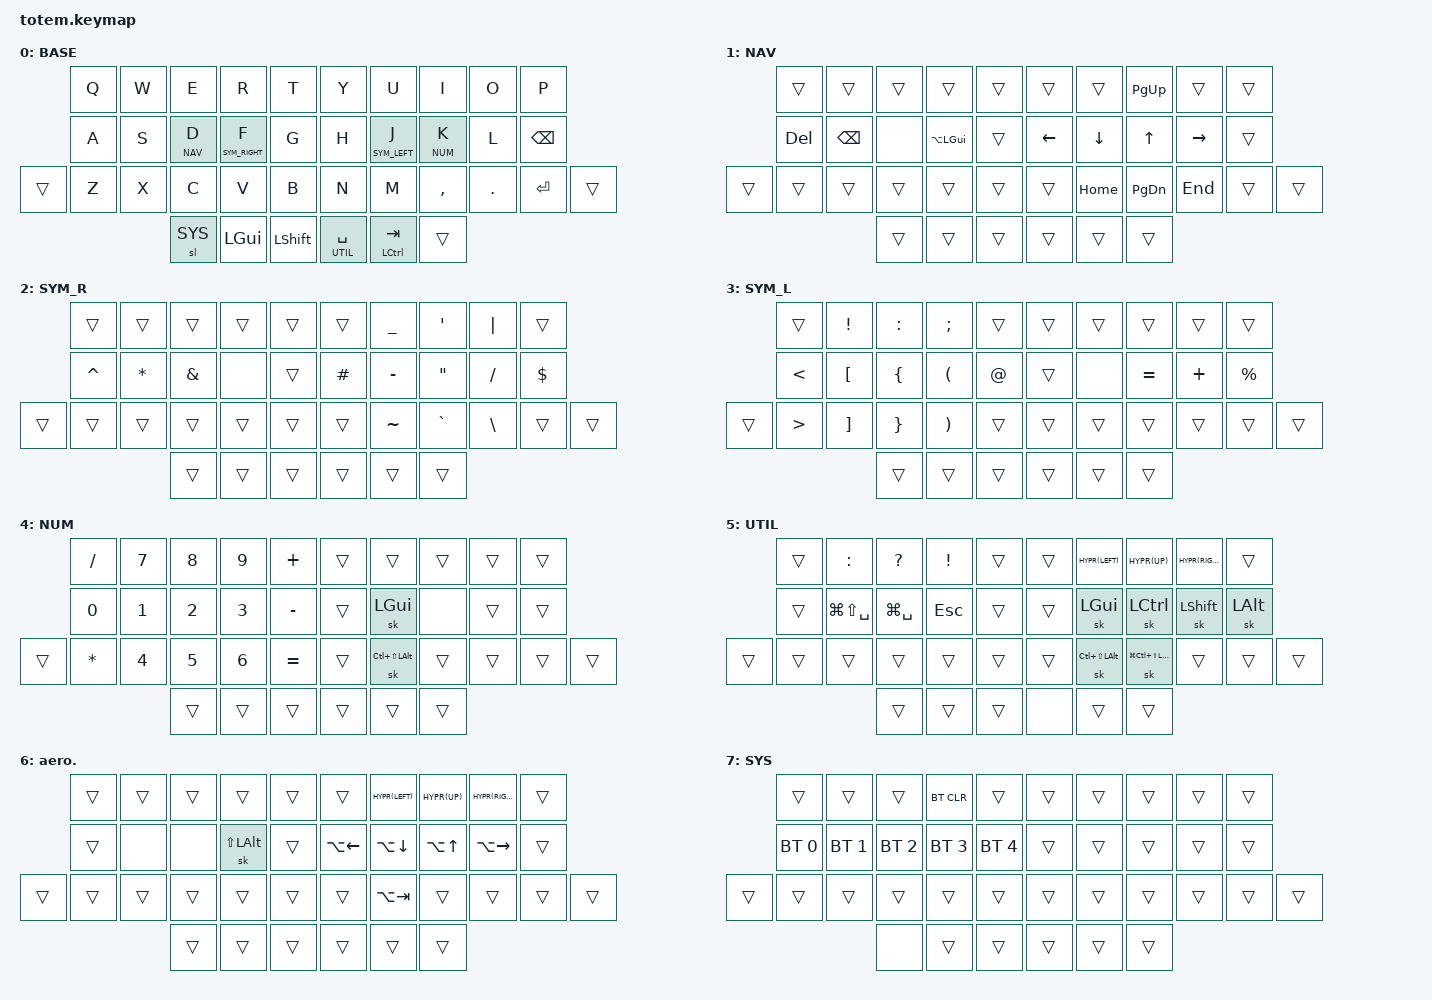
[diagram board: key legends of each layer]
#include <behaviors.dtsi>
#include <dt-bindings/zmk/keys.h>
#include <dt-bindings/zmk/bt.h>
#include <dt-bindings/zmk/outputs.h>

// Layer definitions
#define BASE 0
#define NAV 1
#define SYM_RIGHT 2
#define SYM_LEFT 3
#define NUM 4
#define UTIL 5
#define AERO 6
#define SYS 7

#define QUICK_TAP_MS 175

// QMK-like keycodes
#define _XXX &none
#define ____ &trans

#define _HYPR(kc) &kp LC(LS(LA(LG(kc))))
#define _MEH(kc) &kp LC(LS(LA(kc)))

#define _RAYCAST &kp LG(SPACE)
#define _1PASS &kp LG(LS(SPACE))

// Sticky mods - named explicitly here because I forget what they're are
#define _SK_AERO &sk LS(LALT)
#define _SK_MEH &sk LC(LS(LALT))
#define _SK_HYPR &sk LG(LC(LS(LALT)))

&mt {
  flavor = "balanced";
  tapping-term-ms = <280>;
  quick-tap-ms = <QUICK_TAP_MS>;
  global-quick-tap;
};

&sk {
  release-after-ms = <900>;
  quick-release;
};

&lt {
  flavor = "balanced";
  tapping-term-ms = <200>;
  quick-tap-ms = <QUICK_TAP_MS>;
};

/ {
	combos {
		compatible = "zmk,combos";

		// left ring and index finger
		combo_aero {
			timeout-ms = <200>;
			key-positions = <11 12>;
			bindings = <&mo AERO>;
		};
	};

  keymap {
    compatible = "zmk,keymap";

    base {
      label = "BASE";
      bindings = <
//           ┌───┬───┬──────────┬───────────────┬──────┐   ┌─────────────┬───────────────┬──────────┬───┬──────┐
//           │ Q │ W │    E     │       R       │  T   │   │      Y      │       U       │    I     │ O │  P   │
//           ├───┼───┼──────────┼───────────────┼──────┤   ├─────────────┼───────────────┼──────────┼───┼──────┤
//           │ A │ S │ lt NAV D │ lt SYM_rght F │  G   │   │      H      │ lt SYM_left J │ lt NUM K │ L │ bspc │
//    ┌──────┼───┼───┼──────────┼───────────────┼──────┤   ├─────────────┼───────────────┼──────────┼───┼──────┼──────┐
//    │ ____ │ Z │ X │    C     │       V       │  B   │   │      N      │       M       │    ,     │ . │ ent  │ ____ │
//    └──────┴───┴───┼──────────┼───────────────┼──────┤   ├─────────────┼───────────────┼──────────┼───┴──────┴──────┘
//                   │  sl SYS  │     lgui      │ lsft │   │ lt UTIL spc │ mt lctlTL tab │   ____   │
//                   └──────────┴───────────────┴──────┘   └─────────────┴───────────────┴──────────┘
         &kp Q   &kp W   &kp E       &kp R             &kp T            &kp Y            &kp U            &kp I       &kp O     &kp P
         &kp A   &kp S   &lt NAV D   &lt SYM_RIGHT F   &kp G            &kp H            &lt SYM_LEFT J   &lt NUM K   &kp L     &kp BSPC
  ____   &kp Z   &kp X   &kp C       &kp V             &kp B            &kp N            &kp M            &kp COMMA   &kp DOT   &kp ENTER   ____
                         &sl SYS     &kp LGUI          &kp LSHIFT       &lt UTIL SPACE   &mt LCTL TAB     ____
      >;
    };

    nav {
      label = "NAV";
      bindings = <
//           ┌──────┬──────┬──────┬────────────┬──────┐   ┌──────┬──────┬──────┬──────┬──────┐
//           │ ____ │ ____ │ ____ │    ____    │ ____ │   │ ____ │ ____ │ pgup │ ____ │ ____ │
//           ├──────┼──────┼──────┼────────────┼──────┤   ├──────┼──────┼──────┼──────┼──────┤
//           │ del  │ bspc │ _XXX │ lalt(lgui) │ ____ │   │ left │ down │  up  │ rght │ ____ │
//    ┌──────┼──────┼──────┼──────┼────────────┼──────┤   ├──────┼──────┼──────┼──────┼──────┼──────┐
//    │ ____ │ ____ │ ____ │ ____ │    ____    │ ____ │   │ ____ │ home │ pgdn │ end  │ ____ │ ____ │
//    └──────┴──────┴──────┼──────┼────────────┼──────┤   ├──────┼──────┼──────┼──────┴──────┴──────┘
//                         │ ____ │    ____    │ ____ │   │ ____ │ ____ │ ____ │
//                         └──────┴────────────┴──────┘   └──────┴──────┴──────┘
         ____      ____       ____   ____           ____       ____       ____       &kp PG_UP   ____        ____
         &kp DEL   &kp BSPC   _XXX   &kp LA(LGUI)   ____       &kp LEFT   &kp DOWN   &kp UP      &kp RIGHT   ____
  ____   ____      ____       ____   ____           ____       ____       &kp HOME   &kp PG_DN   &kp END     ____   ____
                              ____   ____           ____       ____       ____       ____
      >;
    };

    sym_right {
      label = "SYM_R";
      bindings = <
//           ┌──────┬──────┬──────┬──────┬──────┐   ┌──────┬──────┬──────┬───┬──────┐
//           │ ____ │ ____ │ ____ │ ____ │ ____ │   │ ____ │  _   │  '   │ | │ ____ │
//           ├──────┼──────┼──────┼──────┼──────┤   ├──────┼──────┼──────┼───┼──────┤
//           │  ^   │  *   │  &   │ _XXX │ ____ │   │  #   │  -   │  "   │ / │  $   │
//    ┌──────┼──────┼──────┼──────┼──────┼──────┤   ├──────┼──────┼──────┼───┼──────┼──────┐
//    │ ____ │ ____ │ ____ │ ____ │ ____ │ ____ │   │ ____ │  ~   │  `   │ \ │ ____ │ ____ │
//    └──────┴──────┴──────┼──────┼──────┼──────┤   ├──────┼──────┼──────┼───┴──────┴──────┘
//                         │ ____ │ ____ │ ____ │   │ ____ │ ____ │ ____ │
//                         └──────┴──────┴──────┘   └──────┴──────┴──────┘
         ____        ____       ____       ____   ____       ____       &kp UNDER   &kp SQT     &kp PIPE   ____
         &kp CARET   &kp STAR   &kp AMPS   _XXX   ____       &kp HASH   &kp MINUS   &kp DQT     &kp FSLH   &kp DOLLAR
  ____   ____        ____       ____       ____   ____       ____       &kp TILDE   &kp GRAVE   &kp BSLH   ____         ____
                                ____       ____   ____       ____       ____        ____
      >;
    };

    sym_left {
      label = "SYM_L";
      bindings = <
//           ┌──────┬───┬──────┬──────┬──────┐   ┌──────┬──────┬──────┬──────┬──────┐
//           │ ____ │ ! │  :   │  ;   │ ____ │   │ ____ │ ____ │ ____ │ ____ │ ____ │
//           ├──────┼───┼──────┼──────┼──────┤   ├──────┼──────┼──────┼──────┼──────┤
//           │  <   │ [ │  {   │  (   │  @   │   │ ____ │ _XXX │ EQL  │  +   │  %   │
//    ┌──────┼──────┼───┼──────┼──────┼──────┤   ├──────┼──────┼──────┼──────┼──────┼──────┐
//    │ ____ │  >   │ ] │  }   │  )   │ ____ │   │ ____ │ ____ │ ____ │ ____ │ ____ │ ____ │
//    └──────┴──────┴───┼──────┼──────┼──────┤   ├──────┼──────┼──────┼──────┴──────┴──────┘
//                      │ ____ │ ____ │ ____ │   │ ____ │ ____ │ ____ │
//                      └──────┴──────┴──────┘   └──────┴──────┴──────┘
         ____     &kp EXCL   &kp COLON   &kp SEMI   ____         ____   ____   ____      ____       ____
         &kp LT   &kp LBKT   &kp LBRC    &kp LPAR   &kp AT       ____   _XXX   &kp EQL   &kp PLUS   &kp PERCENT
  ____   &kp GT   &kp RBKT   &kp RBRC    &kp RPAR   ____         ____   ____   ____      ____       ____          ____
                             ____        ____       ____         ____   ____   ____
      >;
    };

    num {
      label = "NUM";
      bindings = <
//           ┌───┬───┬──────┬──────┬──────┐   ┌──────┬──────────────────────┬──────┬──────┬──────┐
//           │ / │ 7 │  8   │  9   │  +   │   │ ____ │         ____         │ ____ │ ____ │ ____ │
//           ├───┼───┼──────┼──────┼──────┤   ├──────┼──────────────────────┼──────┼──────┼──────┤
//           │ 0 │ 1 │  2   │  3   │  -   │   │ ____ │       &sk lgui       │ _XXX │ ____ │ ____ │
//    ┌──────┼───┼───┼──────┼──────┼──────┤   ├──────┼──────────────────────┼──────┼──────┼──────┼──────┐
//    │ ____ │ * │ 4 │  5   │  6   │ EQL  │   │ ____ │ &sk lctl(lsft(lalt)) │ ____ │ ____ │ ____ │ ____ │
//    └──────┴───┴───┼──────┼──────┼──────┤   ├──────┼──────────────────────┼──────┼──────┴──────┴──────┘
//                   │ ____ │ ____ │ ____ │   │ ____ │         ____         │ ____ │
//                   └──────┴──────┴──────┘   └──────┴──────────────────────┴──────┘
         &kp FSLH   &kp N7   &kp N8   &kp N9   &kp PLUS        ____   ____               ____   ____   ____
         &kp N0     &kp N1   &kp N2   &kp N3   &kp MINUS       ____   &sk LGUI           _XXX   ____   ____
  ____   &kp STAR   &kp N4   &kp N5   &kp N6   &kp EQL         ____   &sk LC(LS(LALT))   ____   ____   ____   ____
                             ____     ____     ____            ____   ____               ____
      >;
    };

    util {
      label = "UTIL";
      bindings = <
//           ┌──────┬────────┬────────────┬──────┬──────┐   ┌──────┬─────────────┬────────────┬─────────────┬──────────┐
//           │ ____ │   :    │     ?      │  !   │ ____ │   │ ____ │ _HYPR(left) │ _HYPR(up)  │ _HYPR(rght) │   ____   │
//           ├──────┼────────┼────────────┼──────┼──────┤   ├──────┼─────────────┼────────────┼─────────────┼──────────┤
//           │ ____ │ _1PASS │ _raltYCAST │ esc  │ ____ │   │ ____ │  &sk lgui   │ &sk lctlTL │  &sk lsft   │ &sk lalt │
//    ┌──────┼──────┼────────┼────────────┼──────┼──────┤   ├──────┼─────────────┼────────────┼─────────────┼──────────┼──────┐
//    │ ____ │ ____ │  ____  │    ____    │ ____ │ ____ │   │ ____ │   _SK_MEH   │  _SK_HYPR  │    ____     │   ____   │ ____ │
//    └──────┴──────┴────────┼────────────┼──────┼──────┤   ├──────┼─────────────┼────────────┼─────────────┴──────────┴──────┘
//                           │    ____    │ ____ │ ____ │   │ _XXX │    ____     │    ____    │
//                           └────────────┴──────┴──────┘   └──────┴─────────────┴────────────┘
         ____   &kp COLON   &kp QMARK   &kp EXCL   ____       ____   _HYPR(LEFT)   _HYPR(UP)   _HYPR(RIGHT)   ____
         ____   _1PASS      _RAYCAST    &kp ESC    ____       ____   &sk LGUI      &sk LCTL    &sk LSHIFT     &sk LALT
  ____   ____   ____        ____        ____       ____       ____   _SK_MEH       _SK_HYPR    ____           ____       ____
                            ____        ____       ____       _XXX   ____          ____
      >;
    };

    aero {
      label = "aero.";
      bindings = <
//           ┌──────┬──────┬──────┬──────────┬──────┐   ┌────────────┬─────────────┬───────────┬─────────────┬──────┐
//           │ ____ │ ____ │ ____ │   ____   │ ____ │   │    ____    │ _HYPR(left) │ _HYPR(up) │ _HYPR(rght) │ ____ │
//           ├──────┼──────┼──────┼──────────┼──────┤   ├────────────┼─────────────┼───────────┼─────────────┼──────┤
//           │ ____ │ _XXX │ _XXX │ _SK_AERO │ ____ │   │ lalt(left) │ lalt(down)  │ lalt(up)  │ lalt(rght)  │ ____ │
//    ┌──────┼──────┼──────┼──────┼──────────┼──────┤   ├────────────┼─────────────┼───────────┼─────────────┼──────┼──────┐
//    │ ____ │ ____ │ ____ │ ____ │   ____   │ ____ │   │    ____    │  lalt(tab)  │   ____    │    ____     │ ____ │ ____ │
//    └──────┴──────┴──────┼──────┼──────────┼──────┤   ├────────────┼─────────────┼───────────┼─────────────┴──────┴──────┘
//                         │ ____ │   ____   │ ____ │   │    ____    │    ____     │   ____    │
//                         └──────┴──────────┴──────┘   └────────────┴─────────────┴───────────┘
         ____   ____   ____   ____       ____       ____           _HYPR(LEFT)    _HYPR(UP)    _HYPR(RIGHT)    ____
         ____   _XXX   _XXX   _SK_AERO   ____       &kp LA(LEFT)   &kp LA(DOWN)   &kp LA(UP)   &kp LA(RIGHT)   ____
  ____   ____   ____   ____   ____       ____       ____           &kp LA(TAB)    ____         ____            ____   ____
                       ____   ____       ____       ____           ____           ____
      >;
    };

    sys {
      label = "SYS";
      bindings = <
//           ┌──────────┬──────────┬──────────┬──────────┬──────────┐   ┌──────┬──────┬──────┬──────┬──────┐
//           │   ____   │   ____   │   ____   │  bt_clr  │   ____   │   │ ____ │ ____ │ ____ │ ____ │ ____ │
//           ├──────────┼──────────┼──────────┼──────────┼──────────┤   ├──────┼──────┼──────┼──────┼──────┤
//           │ bt_sel 0 │ bt_sel 1 │ bt_sel 2 │ bt_sel 3 │ bt_sel 4 │   │ ____ │ ____ │ ____ │ ____ │ ____ │
//    ┌──────┼──────────┼──────────┼──────────┼──────────┼──────────┤   ├──────┼──────┼──────┼──────┼──────┼──────┐
//    │ ____ │   ____   │   ____   │   ____   │   ____   │   ____   │   │ ____ │ ____ │ ____ │ ____ │ ____ │ ____ │
//    └──────┴──────────┴──────────┼──────────┼──────────┼──────────┤   ├──────┼──────┼──────┼──────┴──────┴──────┘
//                                 │   _XXX   │   ____   │   ____   │   │ ____ │ ____ │ ____ │
//                                 └──────────┴──────────┴──────────┘   └──────┴──────┴──────┘
         ____           ____           ____           &bt BT_CLR     ____               ____   ____   ____   ____   ____
         &bt BT_SEL 0   &bt BT_SEL 1   &bt BT_SEL 2   &bt BT_SEL 3   &bt BT_SEL 4       ____   ____   ____   ____   ____
  ____   ____           ____           ____           ____           ____               ____   ____   ____   ____   ____   ____
                                       _XXX           ____           ____               ____   ____   ____
      >;
    };
  };
};
